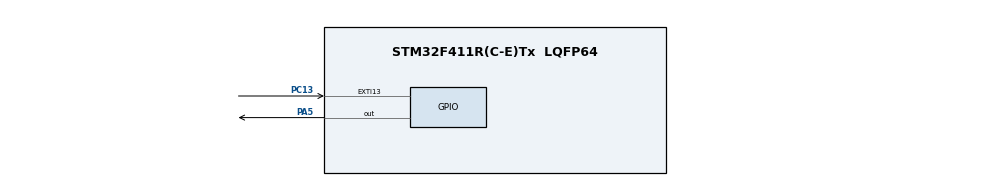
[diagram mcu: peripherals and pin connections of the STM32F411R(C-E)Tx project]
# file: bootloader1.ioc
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Mcu.Family=STM32F4
Mcu.Name=STM32F411R(C-E)Tx
Mcu.Package=LQFP64
NVIC.EXTI15_10_IRQn=true\:0\:0\:false\:false\:true\:true\:true\:true
NVIC.PriorityGroup=NVIC_PRIORITYGROUP_0
PA5.Signal=GPIO_Output
PC13-ANTI_TAMP.Signal=GPXTI13
PH0\ -\ OSC_IN.Mode=HSE-External-Clock-Source
PH0\ -\ OSC_IN.Signal=RCC_OSC_IN
PH1\ -\ OSC_OUT.Mode=HSE-External-Clock-Source
PH1\ -\ OSC_OUT.Signal=RCC_OSC_OUT
ProjectManager.HeapSize=0x200
ProjectManager.StackSize=0x400
ProjectManager.TargetToolchain=STM32CubeIDE
RCC.48MHZClocksFreq_Value=50000000
RCC.AHBFreq_Value=100000000
RCC.APB1CLKDivider=RCC_HCLK_DIV2
RCC.APB1Freq_Value=50000000
RCC.APB1TimFreq_Value=100000000
RCC.APB2Freq_Value=100000000
RCC.APB2TimFreq_Value=100000000
RCC.CortexFreq_Value=100000000
RCC.FLatency-AdvancedSettings=FLASH_LATENCY_3
RCC.HCLKFreq_Value=100000000
RCC.HSE_VALUE=8000000
RCC.HSI_VALUE=16000000
RCC.LSE_VALUE=32768
RCC.PLLM=8
RCC.PLLN=100
RCC.SYSCLKFreq_VALUE=100000000
RCC.SYSCLKSource=RCC_SYSCLKSOURCE_PLLCLK
RCC.VCOOutputFreq_Value=200000000
board=NUCLEO-F411RE

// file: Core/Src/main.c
/* USER CODE BEGIN Header */
/**
  ******************************************************************************
  * @file           : main.c
  * @brief          : Main program body
  ******************************************************************************
  * @attention
  *
  * Copyright (c) 2026 STMicroelectronics.
  * All rights reserved.
  *
  * This software is licensed under terms that can be found in the LICENSE file
  * in the root directory of this software component.
  * If no LICENSE file comes with this software, it is provided AS-IS.
  *
  ******************************************************************************
  */
/* USER CODE END Header */
#include "main.h"
#include "bootloader.h"

void SystemClock_Config(void);
static void MX_GPIO_Init(void);

int main(void)
{

  /* USER CODE BEGIN 1 */
	Bootloader_Init();

	Bootloader_Run();
  /* USER CODE END 1 */

  /* MCU Configuration--------------------------------------------------------*/

  /* Reset of all peripherals, Initializes the Flash interface and the Systick. */
  HAL_Init();

  /* Configure the system clock */
  SystemClock_Config();

  /* Initialize all configured peripherals */
  MX_GPIO_Init();

  /* Infinite loop */
  while (1)
  {

    /* USER CODE BEGIN 3 */
	  LED_BlinkError(10);
	  HAL_Delay(1000);
  }
  /* USER CODE END 3 */
}

static void MX_GPIO_Init(void)
{
  GPIO_InitTypeDef GPIO_InitStruct = {0};

  /* GPIO Ports Clock Enable */
  __HAL_RCC_GPIOC_CLK_ENABLE();
  __HAL_RCC_GPIOH_CLK_ENABLE();
  __HAL_RCC_GPIOA_CLK_ENABLE();

  /*Configure GPIO pin Output Level */
  HAL_GPIO_WritePin(GPIOA, GPIO_PIN_5, GPIO_PIN_RESET);

  /*Configure GPIO pin : PC13 */
  GPIO_InitStruct.Pin = GPIO_PIN_13;
  GPIO_InitStruct.Mode = GPIO_MODE_IT_RISING;
  GPIO_InitStruct.Pull = GPIO_NOPULL;
  HAL_GPIO_Init(GPIOC, &GPIO_InitStruct);

  /*Configure GPIO pin : PA5 */
  GPIO_InitStruct.Pin = GPIO_PIN_5;
  GPIO_InitStruct.Mode = GPIO_MODE_OUTPUT_PP;
  GPIO_InitStruct.Pull = GPIO_NOPULL;
  GPIO_InitStruct.Speed = GPIO_SPEED_FREQ_LOW;
  HAL_GPIO_Init(GPIOA, &GPIO_InitStruct);

  /* EXTI interrupt init*/
  HAL_NVIC_SetPriority(EXTI15_10_IRQn, 0, 0);
  HAL_NVIC_EnableIRQ(EXTI15_10_IRQn);

}

void Error_Handler(void)
{
  __disable_irq();
  while (1)
  {
  }
}
